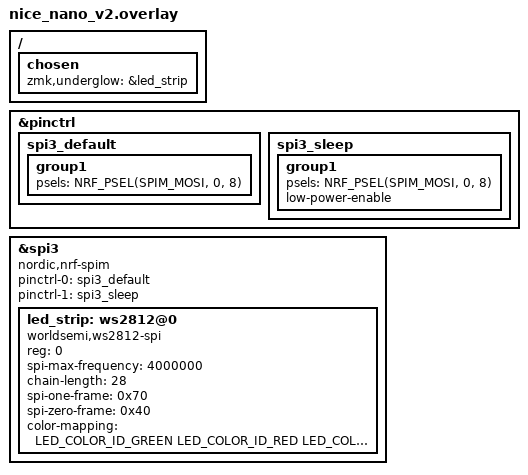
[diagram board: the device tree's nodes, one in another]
/*
 * Per ZMK docs: RGB underglow is configured against a board (not a shield),
 * because the LED-strip driver depends on hardware-specific interfaces
 * (SPI/I2S) that the shield cannot know about. This overlay is conditionally
 * loaded when the voyager_ps shield is built for nice_nano_v2.
 *
 * LED data line is bodged from MCU D0 (P0.08) — high-frequency capable —
 * to LED #1 DIN. The original PCB had LED data on D16 (P0.10) which is an
 * NFC pin marked "low frequency I/O only" in the nRF52840 datasheet and
 * cannot reliably produce WS2812 timing. Cross-connected with row "num"
 * which originally lived on D0 and is now reassigned to D16 (matrix scan
 * is sub-kHz so the low-frequency limit doesn't bite).
 */

#include <dt-bindings/led/led.h>

&pinctrl {
    spi3_default: spi3_default {
        group1 {
            psels = <NRF_PSEL(SPIM_MOSI, 0, 8)>;
        };
    };

    spi3_sleep: spi3_sleep {
        group1 {
            psels = <NRF_PSEL(SPIM_MOSI, 0, 8)>;
            low-power-enable;
        };
    };
};

&spi3 {
    compatible = "nordic,nrf-spim";
    status = "okay";

    pinctrl-0 = <&spi3_default>;
    pinctrl-1 = <&spi3_sleep>;
    pinctrl-names = "default", "sleep";

    led_strip: ws2812@0 {
        compatible = "worldsemi,ws2812-spi";

        /* SPI */
        reg = <0>;
        spi-max-frequency = <4000000>;

        /* WS2812 */
        chain-length = <28>;
        spi-one-frame = <0x70>;
        spi-zero-frame = <0x40>;

        color-mapping = <LED_COLOR_ID_GREEN LED_COLOR_ID_RED LED_COLOR_ID_BLUE>;
    };
};

/ {
    chosen {
        zmk,underglow = &led_strip;
    };
};
